# STM32U5G7 register map
File version: 1.3
CPU: CM33 r0p1, little endian, MPU, FPU, 4 interrupt priority bits
Registers are 32-bit, read-write, reset 0x0 unless marked. A register's access mark holds for its fields unless they carry their own. Offsets are from the block's base; [hi:lo] are bit positions; {n}, {i} and the like mark numbered series; 'fields as' and 'values as' point back to an identical list.

## MDF1 — Multi-function digital filter
Base 0x40025000
Same registers: SEC_MDF1 0x50025000
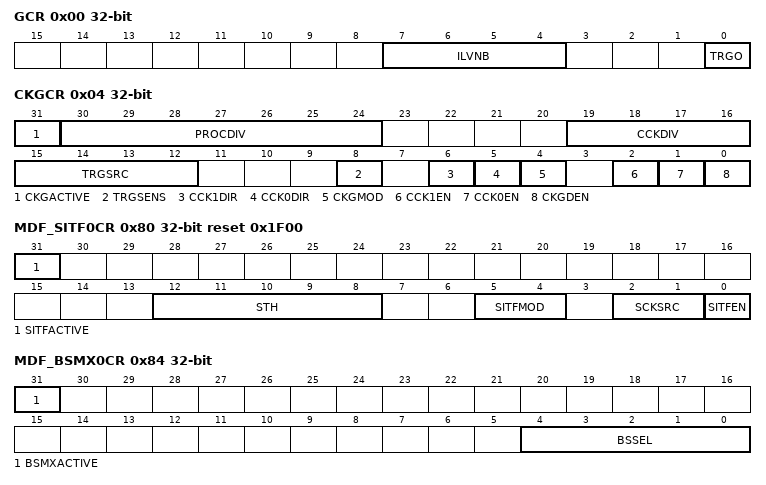
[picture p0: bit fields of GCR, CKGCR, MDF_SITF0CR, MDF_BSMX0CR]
0x00 GCR — MDF global control register
  [7:4] ILVNB, [0] TRGO
0x04 CKGCR — MDF clock generator control register
  [31] CKGACTIVE, [30:24] PROCDIV, [19:16] CCKDIV, [15:12] TRGSRC, [8] TRGSENS, [6] CCK1DIR, [5] CCK0DIR, [4] CKGMOD, [2] CCK1EN, [1] CCK0EN, [0] CKGDEN
0x80 MDF_SITF0CR access per field reset 0x1F00 — This register is used to control the serial interfaces (SITFx).
  [31] SITFACTIVE ro — Serial interface Active flag Set and cleared by hardware. This flag must be used by the application in order to check if the serial interface is effectively enabled (active) or not. The protected fields of this function can only be updated when the SITFACTIVE is set , please refer to Section 1.4.15: Register protection for details. The delay between a transition on SITFEN and a transition on SITFACTIVE is 2 periods of AHB clock and 2 periods of mdf_proc_ck. - 0: The serial interface is not active, and can be configured if needed - 1: The serial interface is active, and protected fields cannot be configured.
  [12:8] STH rw — Manchester Symbol threshold / SPI threshold Set and cleared by software. This field is used for Manchester mode, in order to define the expected symbol threshold levels. Please refer to Section : Manchester mode for details on computation. In addition this field is used to define the timeout value for the clock absence detection in Normal SPI mode. Values of STH[4:0] lower than 4 are invalid. This field can be write-protected, please refer to Section 1.4.15: Register protection for details.
  [5:4] SITFMOD rw — Serial interface type Set and cleared by software. This field is used to defined the serial interface type. - 00: LF_MASTER (Low-Frequency MASTER) SPI mode - 01: Normal SPI mode - 10: Manchester mode: rising edge = logic 0, falling edge = logic 1 - 11: Manchester mode: rising edge = logic 1, falling edge = logic 0 This field can be write-protected, please refer to Section 1.4.15: Register protection for details.
  [2:1] SCKSRC rw — Serial clock source Set and cleared by software. This bit is used to select the clock source of the serial interface. - 00: Serial clock source is MDF_CCK0 - 01: Serial clock source is MDF_CCK1 1x: Serial clock source is MDF_CKIx, not allowed in LF_MASTER SPI mode This field can be write-protected, please refer to Section 1.4.15: Register protection for details.
  [0] SITFEN rw — Serial interface enable Set and cleared by software. This bit is used to enable/disable the serial interface. - 0: Serial interface disabled - 1: Serial interface enabled
0x84 MDF_BSMX0CR access per field — This register is used to select the bitstream to be provided to the corresponding digital filter and to the SCD.
  [31] BSMXACTIVE ro — BSMX Active flag Set and cleared by hardware. This flag must be used by the application in order to check if the BSMX is effectively enabled (active) or not. BSSEL[4:0] can only be updated when the BSMXACTIVE is set . The BSMXACTIVE flag is a logical between OLDACTIVE, DFLTACTIVE, and SCDACTIVE flags. Both of them must be set in order update BSSEL[4:0] field. - 0: The BSMX is not active, and can be configured if needed - 1: The BSMX is active, and protected fields cannot be configured.
  [4:0] BSSEL rw — Bitstream Selection Set and cleared by software. This field is used to select the bitstream to be processed for the digital filter x and for the SCDx. The size of this field depends on the number of DFLTx instantiated. If the BSSEL is selecting an input which is not instantiated, the MDF will select the valid stream bs[x]_F having the higher index number. - 00000: The bitstream bs[0]_R is provided to DFLTx and SCDx - 00001: The bitstream bs[0]_F is provided to DFLTx and SCDx - 00010: The bitstream bs[1]_R is provided to DFLTx and SCDx (if instantiated) - 00011: The bitstream bs[1]_F is provided to DFLTx and SCDx (if instantiated) ... - 11110: The bitstream bs[15]_R is provided to DFLTx and SCDx (if instantiated) - 11111: The bitstream bs[15]_F is provided to DFLTx and SCDx (if instantiated) This field can be write-protected, please refer to Section 1.4.15: Register protection for details.
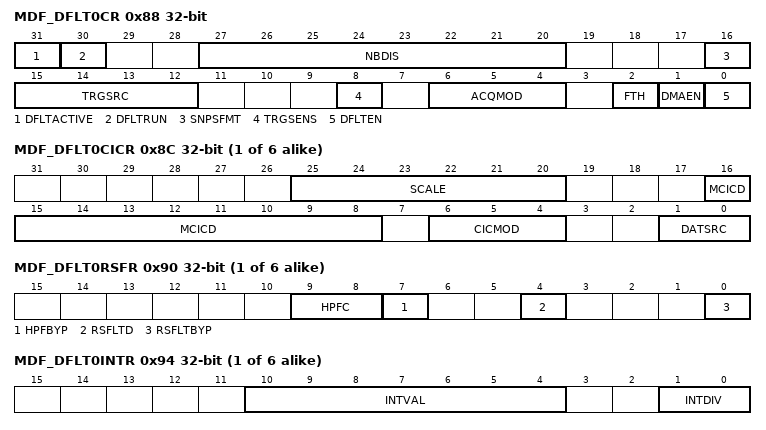
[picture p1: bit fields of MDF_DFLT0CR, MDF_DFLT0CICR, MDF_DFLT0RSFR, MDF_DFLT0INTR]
0x88 MDF_DFLT0CR access per field — This register is used to control the digital filter x.
  [31] DFLTACTIVE ro — Digital filter Active Flag Set and cleared by hardware. This bit indicates if the digital filter is active: can be running or waiting for events. - 0: The digital filter is not active, and can be re-enabled again (via DFLTEN bit) if needed - 1: The digital filter is active
  [30] DFLTRUN ro — Digital filter Run Status Flag Set and cleared by hardware. This bit indicates if the digital filter is running or not. - 0: The digital filter is not running, and ready to accept a new trigger event - 1: The digital filter is running
  [27:20] NBDIS rw — Number of samples to be discarded Set and cleared by software. This field is used to define the number of samples to be discarded every time the DFLTx is re-started. - 0: no sample discarded - 1: 1 sample discarded - 2: 2 samples discarded ... - 255: 255 samples discarded This field can be write-protected, please refer to Section 1.4.15: Register protection for details.
  [16] SNPSFMT rw — Snapshot data format Set and cleared by software. This field is used to select the data format for the snapshot mode. - 0: The integrator counter (INT_CNT) is not inserted into the MDF_SNPSxDR register, leaving a data resolution of 23 bits. - 1: The integrator counter (INT_CNT) is inserted at position [15:9] of MDF_SNPSxDR register, leaving a data resolution of 16 bits. This field can be write-protected, please refer to Section 1.4.15: Register protection for details.
  [15:12] TRGSRC rw — Digital filter Trigger signal selection, Set and cleared by software. This field is used to select which external signals is used as trigger for the corresponding filter. - 0000: TRGO is selected - 0001: OLDx event is selected - 0010: mdf_trg[0] is selected ... - 1111: mdf_trg[13] is selected This field can be write-protected, please refer to Section 1.4.15: Register protection for details.
  [8] TRGSENS rw — Digital filter Trigger sensitivity selection Set and cleared by software. This field is used to select the trigger sensitivity of the external signals - 0: A rising edge event triggers the acquisition - 1: A falling edge even triggers the acquisition Note that when the trigger source is TRGO or OLDx event, TRGSENS value is not taken into account. When TRGO is selected, the sensitivity is forced to falling edge, when OLDx event is selected, the sensitivity is forced to rising edge. This field can be write-protected, please refer to Section 1.4.15: Register protection for details.
  [6:4] ACQMOD rw — Digital filter Trigger mode Set and cleared by software. This field is used to select the filter trigger mode. - 000: Asynchronous, continuous acquisition mode - 001: Asynchronous, single-shot acquisition mode - 010: Synchronous, continuous acquisition mode - 011: Synchronous, single-shot acquisition mode - 100: Window, continuous acquisition mode - 101: Synchronous, snapshot mode others: same a 000 This field can be write-protected, please refer to Section 1.4.15: Register protection for details.
  [2] FTH rw — RXFIFO Threshold selection Set and cleared by software.
  [1] DMAEN rw — DMA Requests Enable Set and cleared by software. This bit is used to control the generation of DMA request in order to transfer the processed samples into the memory. - 0: The DMA interface for the corresponding digital filter is disabled - 1: The DMA interface for the corresponding digital filter is enabled This field can be write-protected, please refer to Section 1.4.15: Register protection for details.
  [0] DFLTEN wo — Digital Filter Enable Set and cleared by software. This bit is used to control the start of acquisition of the corresponding digital filter path. The behavior of this bit depends on ACQMOD and external events. or the acquisition starts when the proper trigger event occurs if ACQMOD = 01x . The serial or parallel interface delivering the samples shall be enabled as well. - 0: The acquisition is stopped immediately - 1: The acquisition is immediately started if ACQMOD = 00x or 1xx ,
{0x8C+0x80*i} MDF_DFLT{i}CICR (i=0..5) — This register is used to control the main CIC filter.
  [25:20] SCALE — Scaling factor selection Set and cleared by software. This field is used to allow the application to select the gain to be applied at CIC output. Please refer to Table 13: Possible gain values for details. If the application attempts to write a new gain value while the previous one is not yet applied, this new gain value is ignored. Reading back the SCALE[5:0] field will inform the application on the current gain value. - 100000: - 48.2 dB, or shift right by 8 bits (default value) - 100001: - 44.6 dB, - 100010: - 42.1 dB, or shift right by 7 bits - 100011: - 38.6 dB, ... - 101110: -6 dB, or shift right by 1 bit - 101111: -2.5 dB, - 000000: 0 dB - 000001: + 3.5 dB, - 000010: + 6 dB, or shift left by 1 bit ... - 011000: + 72 dB, or shift left by 12 bits
  [16:8] MCICD — CIC decimation ratio selection Set and cleared by software. This bit is used to allow the application to select the decimation ratio of the CIC. Decimation ratio smaller than 2 is not allowed. The decimation ratio is given by (CICDEC+1). - 0: Decimation ratio is 2 - 1: Decimation ratio is 2 - 2: Decimation ratio is 3 - 3: Decimation ratio is 4 ... - 511: Decimation ratio is 512 This field can be write-protected, please refer to Section 1.4.15: Register protection for details.
  [6:4] CICMOD — Select the CIC mode Set and cleared by software. This field allows the application to select the configuration and the order of the MCIC. When CICMOD[2:0] is equal to 0xx , the CIC is split into two filters: - The main CIC (MCIC) - The auxiliary CIC (ACIC), used for the out-off limit detector - 000: The CIC is split into 2 filters, and the main CIC (MCIC) is configured in FastSinc filter - 001: The CIC is split into 2 filters, and the main CIC (MCIC) is configured in Sinc1 filter - 010: The CIC is split into 2 filters, and the main CIC (MCIC) is configured in Sinc2 filter - 011: The CIC is split into 2 filters, and the main CIC (MCIC) is configured in Sinc3 filter - 100: The CIC is configured in single sinc4 filter others: The CIC is configured in single sinc5 filter This field can be write-protected, please refer to Section 1.4.15: Register protection for details.
  [1:0] DATSRC — Source data for the digital filter Set and cleared by software. 0x: Select the stream coming from the BSMX - 10: Select the stream coming from the ADCITF1 - 11: Select the stream coming from the ADCITF2 This field can be write-protected, please refer to Section 1.4.15: Register protection for details.
{0x90+0x80*i} MDF_DFLT{i}RSFR (i=0..5) — This register is used to control the reshape and HPF filters.
  [9:8] HPFC — High-pass filter cut-off frequency Set and cleared by software. This field is used to select the cut-off frequency of the high-pass filter. FPCM represents the sampling frequency at HPF input. - 00: Cut-off frequency = 0.000625 x FPCM - 01: Cut-off frequency = 0.00125 x FPCM - 10: Cut-off frequency = 0.00250 x FPCM - 11: Cut-off frequency = 0.00950 x FPCM This field can be write-protected, please refer to Section 1.4.15: Register protection for details.
  [7] HPFBYP — High-Pass Filter bypass Set and cleared by software. This bit is used to bypass the high-pass filter. - 0: The high pass filter is not bypassed (Default value) - 1: The high pass filter is bypassed This field can be write-protected, please refer to Section 1.4.15: Register protection for details.
  [4] RSFLTD — Reshaper filter decimation ratio Set and cleared by software. This bit is used to select the decimation ratio for the reshape filter - 0: Decimation ratio is 4 (Default value) - 1: Decimation ratio is 1 This field can be write-protected, please refer to Section 1.4.15: Register protection for details.
  [0] RSFLTBYP — Reshaper filter bypass Set and cleared by software. This bit is used to bypass the reshape filter and its decimation block. - 0: The reshape filter is not bypassed (Default value) - 1: The reshape filter is bypassed This field can be write-protected, please refer to Section 1.4.15: Register protection for details.
{0x94+0x80*i} MDF_DFLT{i}INTR (i=0..5) — This register is used to the integrator (INT) settings.
  [10:4] INTVAL — Integration value selection Set and cleared by software. This field is used to select the integration value. - 0: The integration value is 1, meaning bypass mode (default after reset) - 1: The integration value is 2 - 2: The integration value is 3 ... - 127: The integration value is 128 This field can be write-protected, please refer to Section 1.4.15: Register protection for details.
  [1:0] INTDIV — Integrator output division Set and cleared by software. This bit is used to rescale the signal at the integrator output in order keep the data width lower than 24 bits. - 00: The integrator data outputs are divided by 128 (Default value) - 01: The integrator data outputs are divided by 32 - 10: The integrator data outputs are divided by 4 - 11: The integrator data outputs are not divided This field can be write-protected, please refer to Section 1.4.15: Register protection for details.
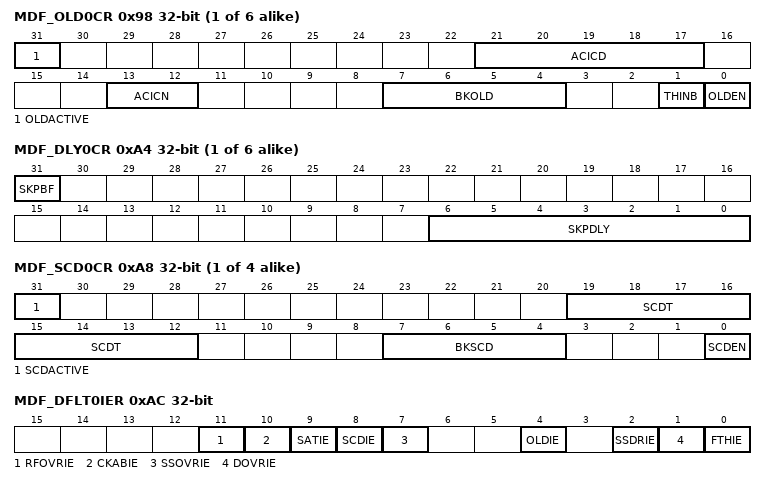
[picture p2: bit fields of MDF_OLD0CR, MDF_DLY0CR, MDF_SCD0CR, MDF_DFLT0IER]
{0x98+0x80*i} MDF_OLD{i}CR access per field (i=0..5) — This register is used to configure the Out-of Limit Detector function.
  [31] OLDACTIVE ro — OLD Active flag Set and cleared by hardware. This flag must be used by the application in order to check if the OLD is effectively enabled (active) or not. The protected fields and registers of this function can only be updated when the OLDACTIVE is set to , please refer to Section 1.4.15: Register protection for details. The delay between a transition on OLDEN and a transition on OLDACTIVE is 2 periods of AHB clock and 2 periods of mdf_proc_ck. - 0: The OLD is not active, and can be configured if needed - 1: The OLD is active, and protected fields cannot be configured.
  [21:17] ACICD rw — OLD CIC decimation ratio selection Set and cleared by software. This field is used to allow the application to select the decimation ratio of the ACIC. This field is only taken into account by the MDF when CICMOD[2:0] = 0xx . The decimation ratio is given by (ACICD+1). - 0: Decimation ratio is 1 - 1: Decimation ratio is 2 - 2: Decimation ratio is 3 - 3: Decimation ratio is 4 ... - 31: Decimation ratio is 32 This field can be write-protected, please refer to Section 1.4.15: Register protection for details.
  [13:12] ACICN rw — OLD CIC order selection Set and cleared by software. This field allows the application to select the type, and the order of the ACIC. This field is only taken into account by the MDF when CICMOD[2:0] = 0xx . - 00: FastSinc filter type - 01: Sinc1 filter type - 10: Sinc2 filter type - 11: Sinc3 filter type This field can be write-protected, please refer to Section 1.4.15: Register protection for details.
  [7:4] BKOLD rw — Break signal assignment for out-of limit detector Set and cleared by software. BKOLD[i] = 0: Break signal (mdf_break[i]) is not assigned to threshold event BKOLD[i] = 1: Break signal (mdf_break[i]) is assigned to threshold event This field can be write-protected, please refer to Section 1.4.15: Register protection for details.
  [1] THINB rw — Threshold In band Set and cleared by software. - 0: The OLD generates an event if the signal is lower than OLDTHL OR higher than OLDTHH (Default value) - 1: The OLD generates an event if the signal is lower than OLDTHH AND higher than OLDTHL This field can be write-protected, please refer to Section 1.4.15: Register protection for details.
  [0] OLDEN rw — Over-Current Detector Enable Set and cleared by software. - 0: The OLD is disabled (Default value) - 1: The OLD is enabled, including the ACIC filter working in continuous mode.
{0x9C+0x80*i} MDF_OLD{i}THLR (i=0..5) — This register is used for the adjustment of the Out-off Limit low threshold.
  [25:0] OLDTHL — OLD Low Threshold Value Set and cleared by software. OLDTHL represents a 26-bit signed value. The real threshold compared to the signal provided by the filter is OLDTHL. This field can be write-protected, please refer to Section 1.4.15: Register protection for details.
{0xA0+0x80*i} MDF_OLD{i}THHR (i=0..5) — This register is used for the adjustment of the Out-off Limit high threshold.
  [25:0] OLDTHH — OLD High Threshold Value Set and cleared by software. OLDTHH represents a 26-bit signed value. The real threshold compared to the signal provided by the filter is OLDTHH. This field can be write-protected, please refer to Section 1.4.15: Register protection for details
{0xA4+0x80*i} MDF_DLY{i}CR access per field (i=0..5) — This register is used for the adjustment stream delays.
  [31] SKPBF ro — Skip Busy flag Set and cleared by hardware. Shall be used in order to control if the delay sequence is completed. - 0: Reading 0 means that the MDF is ready to accept a new value into SKPDLY[6:0]. - 1: Reading 1 means that last valid SKPDLY[6:0] is still under precessing.
  [6:0] SKPDLY rw — Delay to apply to a bitstream Set and cleared by software. Defines the number of input samples that will be skipped. Skipping is applied immediately after writing to this field, if SKPBF = 0 , and the corresponding bit DFLTEN = 1 . If SKPBF = 1 the value written into the register is ignored by the delay state machine. - 0: No input sample skipped, - 1: 1 input sample skipped, ... - 127: 127 input sample skipped,
{0xA8+0x80*i} MDF_SCD{i}CR access per field (i=0..3) — This register is used for the adjustment stream delays.
  [31] SCDACTIVE ro — SCD Active flag Set and cleared by hardware. This flag must be used by the application in order to check if the SCD is effectively enabled (active) or not. The protected fields of this function can only be updated when the SCDACTIVE is set to a , please refer to Section 1.4.15: Register protection for details. The delay between a transition on SCDEN and a transition on SCDACTIVE is 2 periods of AHB clock and 2 periods of mdf_proc_ck. - 0: The SCD is not active, and can be configured if needed - 1: The SCD is active, and protected fields cannot be configured.
  [19:12] SCDT rw — Short-circuit detector threshold Set and cleared by software. These bits are written by software to define the threshold counter for the short-circuit detector. If this value is reached, then a short-circuit detector event occurs on a given input stream. - 0: 2 consecutive 1 s or 0 s will generate an event, - 1: 2 consecutive 1 s or 0 s will generate an event - 2: 3 consecutive 1 s or 0 s will generate an event, ... - 255: 256 consecutive 1 s or 0 s will generate an event, This field can be write-protected, please refer to Section 1.4.15: Register protection for details.
  [7:4] BKSCD rw — Break signal assignment for short circuit detector Set and cleared by software. BKSCD[i] = 0: Break signal (mdf_break[i]) is not assigned to this SCD event BKSCD[i] = 1: Break signal (mdf_break[i]) is assigned to this SCD event This field can be write-protected, please refer to Section 1.4.15: Register protection for details.
  [0] SCDEN rw — Short circuit detector enable Set and cleared by software. - 0: The short circuit detector is disabled, - 1: The short circuit detector is enabled,
0xAC MDF_DFLT0IER — This register is used for allowing or not the events to generate an interrupt.
  [11] RFOVRIE — Reshape Filter Overrun interrupt enable Set and cleared by software. - 0: Reshape filter overrun interrupt disabled - 1: Reshape filter overrun interrupt enabled
  [10] CKABIE — Clock absence detection interrupt enable Set and cleared by software. - 0: Clock absence interrupt disabled - 1: Clock absence interrupt enabled
  [9] SATIE — Saturation detection interrupt enable Set and cleared by software. - 0: Saturation interrupt disabled - 1: Saturation interrupt enabled
  [8] SCDIE — Short-Circuit Detector interrupt enable Set and cleared by software. - 0: SCD interrupt disabled - 1: SCD interrupt enabled
  [7] SSOVRIE — Snapshot overrun interrupt enable Set and cleared by software. - 0: Snapshot overrun interrupt disabled - 1: Snapshot overrun interrupt enabled
  [4] OLDIE — Out-of Limit interrupt enable Set and cleared by software. - 0: OLD event interrupt disabled - 1: OLD event interrupt enabled
  [2] SSDRIE — Snapshot data ready interrupt enable Set and cleared by software. - 0: Snapshot data ready interrupt disabled - 1: Snapshot data ready interrupt enabled
  [1] DOVRIE — Data overflow interrupt enable Set and cleared by software. - 0: Data overflow interrupt disabled - 1: Data overflow interrupt enabled
  [0] FTHIE — RXFIFO threshold interrupt enable Set and cleared by software. - 0: RXFIFO threshold interrupt disabled - 1: RXFIFO threshold interrupt enabled
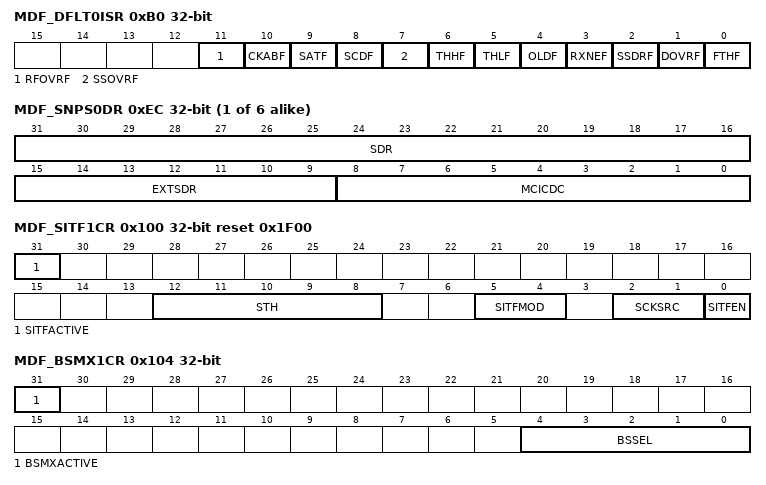
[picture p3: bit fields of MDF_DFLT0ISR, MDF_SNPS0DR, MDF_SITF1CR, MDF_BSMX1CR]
0xB0 MDF_DFLT0ISR access per field — MDF DFLT0 interrupt status register 0
  [11] RFOVRF rw — Reshape Filter Overrun detection flag Set by hardware, and cleared by software by writing this bit to 1 . - 0: Reading 0 means that no reshape filter overrun is detected, writing 0 has no effect. - 1: Reading 1 means that reshape filter overrun is detected, writing 1 clears this flag.
  [10] CKABF rw — Clock absence detection flag Set by hardware, and cleared by software by writing this bit to 1 . - 0: Reading 0 means that no clock absence is detected, writing 0 has no effect. - 1: Reading 1 means that a clock absence is detected, writing 1 clears this flag.
  [9] SATF rw — Saturation detection flag Set by hardware, and cleared by software by writing this bit to 1 . - 0: Reading 0 means that no saturation is detected, writing 0 has no effect. - 1: Reading 1 means that a saturation is detected, writing 1 clears this flag.
  [8] SCDF rw — Short-Circuit Detector flag Set by hardware, and cleared by software by writing this bit to 1 . - 0: Reading 0 means that no SCD event is detected, writing 0 has no effect. - 1: Reading 1 means that a SCD event is detected, writing 1 clears this flag.
  [7] SSOVRF rw — Snapshot overrun flag Set by hardware, and cleared by software by writing this bit to 1 . - 0: Reading 0 means that no snapshot overrun event is detected, writing 0 has no effect. - 1: Reading 1 means that a snapshot overrun event is detected, writing 1 clears this flag.
  [6] THHF ro — High threshold status flag Set by hardware, and cleared by software by writing this bit to 1 . This flag indicates the status of the high threshold comparator when the last OLD event occurred. This bit gives additional information on the conditions triggering the last OLD event. It can be cleared by writing OLDF flag to a 1. - 0: The signal was lower than OLDTHH when the last OLD event occurred. - 1: The signal was higher than OLDTHH when the last OLD event occurred.
  [5] THLF ro — Low threshold status flag Set by hardware, and cleared by software by writing this bit to 1 . This flag indicates the status of the low threshold comparator when the last OLD event occurred. This bit gives additional information on the conditions triggering the last OLD event. It can be cleared by writing OLDF flag to a 1. - 0: The signal was higher than OLDTHL when the last OLD event occurred. - 1: The signal was lower than OLDTHL when the last OLD event occurred.
  [4] OLDF rw — Out-of Limit Detector flag Set by hardware, and cleared by software by writing this bit to 1 . - 0: Reading 0 means that no OLD event is detected, writing 0 has no effect. - 1: Reading 1 means that an OLD event is detected, writing 1 clears THHF, THLF and OLDF flags.
  [3] RXNEF ro — RXFIFO Not Empty flag Set and cleared by hardware according to the RXFIFO level. - 0: Reading 0 means that the RXFIFO is empty. - 1: Reading 1 means that the RXFIFO is not empty.
  [2] SSDRF rw — Snapshot data ready flag Set by hardware, and cleared by software by writing this bit to 1 . - 0: Reading 0 means that no data is available on , writing 0 has no effect. - 1: Reading 1 means that a new data is available on , writing 1 clears this flag.
  [1] DOVRF rw — Data overflow flag Set by hardware, and cleared by software by writing this bit to 1 . - 0: Reading 0 means that no overflow is detected, writing 0 has no effect. - 1: Reading 1 means that an overflow is detected, writing 1 clears this flag.
  [0] FTHF ro
{0xB4+0x80*i} MDF_OEC{i}CR (i=0..5) — This register contains the offset compensation value.
  [25:0] OFFSET — Offset error compensation Set and cleared by software. If the application attempts to write a new offset value while the previous one is not yet applied, this new offset value is ignored. Reading back the OFFSET[25:0] field will inform the application on the current offset value. OFFSET[25:0] represents the value to be subtracted to the signal before going to the SCALE.
{0xEC+0x80*i} MDF_SNPS{i}DR ro (i=0..5) — This register is used to read the data processed by each digital filter in snapshot mode.
  [31:16] SDR — Contains the 16 MSB of the last valid data processed by the digital filter.
  [15:9] EXTSDR — Extended data size If SNPSFMT = 0 , EXTSDR[6:0] contains the bit 7 to 1 of the last valid data processed by the digital filter, If SNPSFMT = 1 , this field contains the INT accumulator counter value at the moment of the last trigger event occurs (INT_CNT).
  [8:0] MCICDC — Contains the MCIC decimation counter value at the moment of the last trigger event occurs (MCIC_CNT)
{0xF0+0x80*i} MDF_DFLT{i}DR ro (i=0..5) — This register is used to read the data processed by each digital filter.
  [31:8] DR — Data processed by digital filter.
0x100 MDF_SITF1CR access per field reset 0x1F00 — This register is used to control the serial interfaces (SITFx).
  [31] SITFACTIVE ro — Serial interface Active flag
  [12:8] STH rw — Manchester Symbol threshold / SPI threshold Set and cleared by software. This field is used for Manchester mode, in order to define the expected symbol threshold levels. Please refer to Section : Manchester mode for details on computation. In addition this field is used to define the timeout value for the clock absence detection in Normal SPI mode. Values of STH[4:0] lower than 4 are invalid. This field can be write-protected, please refer to Section 1.4.15: Register protection for details.
  [5:4] SITFMOD rw — Serial interface type Set and cleared by software. This field is used to defined the serial interface type. - 00: LF_MASTER (Low-Frequency MASTER) SPI mode - 01: Normal SPI mode - 10: Manchester mode: rising edge = logic 0, falling edge = logic 1 - 11: Manchester mode: rising edge = logic 1, falling edge = logic 0 This field can be write-protected, please refer to Section 1.4.15: Register protection for details.
  [2:1] SCKSRC rw — Serial clock source Set and cleared by software. This bit is used to select the clock source of the serial interface. - 00: Serial clock source is MDF_CCK0 - 01: Serial clock source is MDF_CCK1 1x: Serial clock source is MDF_CKIx, not allowed in LF_MASTER SPI mode This field can be write-protected, please refer to Section 1.4.15: Register protection for details.
  [0] SITFEN rw — Serial interface enable Set and cleared by software. This bit is used to enable/disable the serial interface. - 0: Serial interface disabled - 1: Serial interface enabled
0x104 MDF_BSMX1CR access per field — This register is used to select the bitstream to be provided to the corresponding digital filter and to the SCD.
  fields as MDF_BSMX0CR
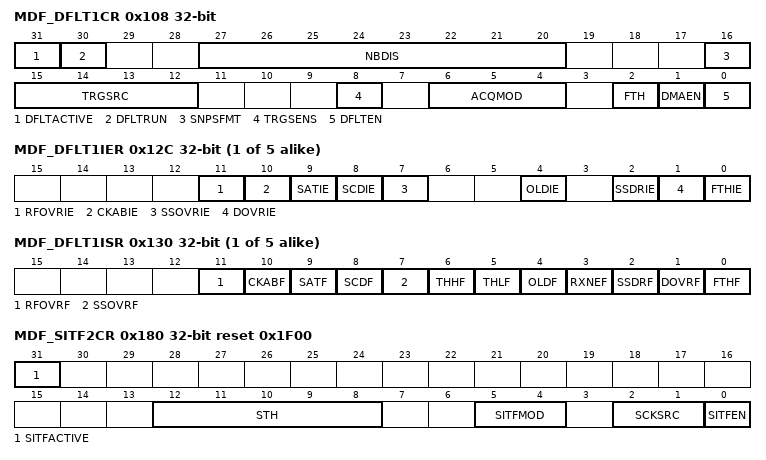
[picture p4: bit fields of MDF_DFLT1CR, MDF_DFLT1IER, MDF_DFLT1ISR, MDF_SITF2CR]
0x108 MDF_DFLT1CR access per field — This register is used to control the digital filter x.
  [31] DFLTACTIVE ro — Digital filter Active Flag Set and cleared by hardware. This bit indicates if the digital filter is active: can be running or waiting for events. - 0: The digital filter is not active, and can be re-enabled again (via DFLTEN bit) if needed - 1: The digital filter is active
  [30] DFLTRUN ro — Digital filter Run Status Flag Set and cleared by hardware. This bit indicates if the digital filter is running or not. - 0: The digital filter is not running, and ready to accept a new trigger event - 1: The digital filter is running
  [27:20] NBDIS rw — Number of samples to be discarded Set and cleared by software. This field is used to define the number of samples to be discarded every time the DFLTx is re-started. - 0: no sample discarded - 1: 1 sample discarded - 2: 2 samples discarded ... - 255: 255 samples discarded This field can be write-protected, please refer to Section 1.4.15: Register protection for details.
  [16] SNPSFMT rw — Snapshot data format Set and cleared by software. This field is used to select the data format for the snapshot mode. - 0: The integrator counter (INT_CNT) is not inserted into the MDF_SNPSxDR register, leaving a data resolution of 23 bits. - 1: The integrator counter (INT_CNT) is inserted at position [15:9] of MDF_SNPSxDR register, leaving a data resolution of 16 bits. This field can be write-protected, please refer to Section 1.4.15: Register protection for details.
  [15:12] TRGSRC rw — Digital filter Trigger signal selection, Set and cleared by software. This field is used to select which external signals is used as trigger for the corresponding filter. - 0000: TRGO is selected - 0001: OLDx event is selected - 0010: mdf_trg[0] is selected ... - 1111: mdf_trg[13] is selected This field can be write-protected, please refer to Section 1.4.15: Register protection for details.
  [8] TRGSENS rw — Digital filter Trigger sensitivity selection Set and cleared by software. This field is used to select the trigger sensitivity of the external signals - 0: A rising edge event triggers the acquisition - 1: A falling edge even triggers the acquisition Note that when the trigger source is TRGO or OLDx event, TRGSENS value is not taken into account. When TRGO is selected, the sensitivity is forced to falling edge, when OLDx event is selected, the sensitivity is forced to rising edge. This field can be write-protected, please refer to Section 1.4.15: Register protection for details.
  [6:4] ACQMOD rw — Digital filter Trigger mode Set and cleared by software. This field is used to select the filter trigger mode. - 000: Asynchronous, continuous acquisition mode - 001: Asynchronous, single-shot acquisition mode - 010: Synchronous, continuous acquisition mode - 011: Synchronous, single-shot acquisition mode - 100: Window, continuous acquisition mode - 101: Synchronous, snapshot mode others: same a 000 This field can be write-protected, please refer to Section 1.4.15: Register protection for details.
  [2] FTH rw — RXFIFO Threshold selection Set and cleared by software. This bit is used to select the RXFIFO threshold. This bit is not significant for RXFIFOs working in interleaved transfer mode. Refer to Section 1.4.13.4: Using the interleaved transfer mode for details. - 0: RXFIFO threshold event generated when the RXFIFO is not empty - 1: RXFIFO threshold event generated when the RXFIFO is half-full This field can be write-protected, please refer to Section 1.4.15: Register protection for details.
  [1] DMAEN rw — DMA Requests Enable Set and cleared by software. This bit is used to control the generation of DMA request in order to transfer the processed samples into the memory. - 0: The DMA interface for the corresponding digital filter is disabled - 1: The DMA interface for the corresponding digital filter is enabled This field can be write-protected, please refer to Section 1.4.15: Register protection for details.
  [0] DFLTEN wo — Digital Filter Enable Set and cleared by software. This bit is used to control the start of acquisition of the corresponding digital filter path. The behavior of this bit depends on ACQMOD and external events. or the acquisition starts when the proper trigger event occurs if ACQMOD = 01x . The serial or parallel interface delivering the samples shall be enabled as well. - 0: The acquisition is stopped immediately - 1: The acquisition is immediately started if ACQMOD = 00x or 1xx ,
{0xAC+0x80*i} MDF_DFLT{i}IER (i=1..5) — MDF DFLTx interrupt enable register x
  fields as MDF_DFLT0IER
{0xB0+0x80*i} MDF_DFLT{i}ISR access per field (i=1..5) — This register contains the status flags for each digital filter path.
  [11] RFOVRF rw — Reshape Filter Overrun detection flag Set by hardware, and cleared by software by writing this bit to 1 . - 0: Reading 0 means that no reshape filter overrun is detected, writing 0 has no effect. - 1: Reading 1 means that reshape filter overrun is detected, writing 1 clears this flag.
  [10] CKABF rw — Clock absence detection flag Set by hardware, and cleared by software by writing this bit to 1 . - 0: Reading 0 means that no clock absence is detected, writing 0 has no effect. - 1: Reading 1 means that a clock absence is detected, writing 1 clears this flag.
  [9] SATF rw — Saturation detection flag Set by hardware, and cleared by software by writing this bit to 1 . - 0: Reading 0 means that no saturation is detected, writing 0 has no effect. - 1: Reading 1 means that a saturation is detected, writing 1 clears this flag.
  [8] SCDF rw — Short-Circuit Detector flag Set by hardware, and cleared by software by writing this bit to 1 . - 0: Reading 0 means that no SCD event is detected, writing 0 has no effect. - 1: Reading 1 means that a SCD event is detected, writing 1 clears this flag.
  [7] SSOVRF rw — Snapshot overrun flag Set by hardware, and cleared by software by writing this bit to 1 . - 0: Reading 0 means that no snapshot overrun event is detected, writing 0 has no effect. - 1: Reading 1 means that a snapshot overrun event is detected, writing 1 clears this flag.
  [6] THHF ro — High threshold status flag Set by hardware, and cleared by software by writing OLDF bit to 1 . This flag indicates the status of the high threshold comparator when the last OLD event occurred. This bit gives additional information on the conditions triggering the last OLD event. It can be cleared by writing OLDF flag to a 1. - 0: The signal was lower than OLDTHH, when the last OLD event occurred - 1: The signal was higher than OLDTHH, when the last OLD event occurred
  [5] THLF ro — Low threshold status flag Set by hardware, and cleared by software by writing OLDF bit to 1 . This flag indicates the status of the low threshold comparator when the last OLD event occurred. This bit gives additional information on the conditions triggering the last OLD event. It can be cleared by writing OLDF flag to a 1. - 0: The signal was lower than OLDTHL, when the last OLD event occurred - 1: The signal was higher than OLDTHL, when the last OLD event occurred
  [4] OLDF rw — Out-of Limit Detector flag Set by hardware, and cleared by software by writing this bit to 1 . - 0: Reading 0 means that no OLD event is detected, writing 0 has no effect. - 1: Reading 1 means that an OLD event is detected, writing 1 clears THHF, THLF and OLDF flags.
  [3] RXNEF ro — RXFIFO Not Empty flag Set and cleared by hardware according to the RXFIFO level. - 0: Reading 0 means that the RXFIFO is empty. - 1: Reading 1 means that the RXFIFO is not empty.
  [2] SSDRF rw — Snapshot data ready flag Set by hardware, and cleared by software by writing this bit to 1 . - 0: Reading 0 means that no data is available on MDF_SNPSxDR, writing 0 has no effect. - 1: Reading 1 means that a new data is available on MDF_SNPSxDR, writing 1 clears this flag.
  [1] DOVRF rw — Data overflow flag Set by hardware, and cleared by software by writing this bit to 1 . - 0: Reading 0 means that no overflow is detected, writing 0 has no effect. - 1: Reading 1 means that an overflow is detected, writing 1 clears this flag.
  [0] FTHF ro — RXFIFO threshold flag Set by hardware, and cleared by software by writing this bit to 1 . - 0: Reading 0 means that the RXFIFO threshold is not reached, writing 0 has no effect. - 1: Reading 1 means that the RXFIFO reached the threshold, writing 1 clears this flag.
0x180 MDF_SITF2CR access per field reset 0x1F00 — This register is used to control the serial interfaces (SITFx).
  fields as MDF_SITF1CR
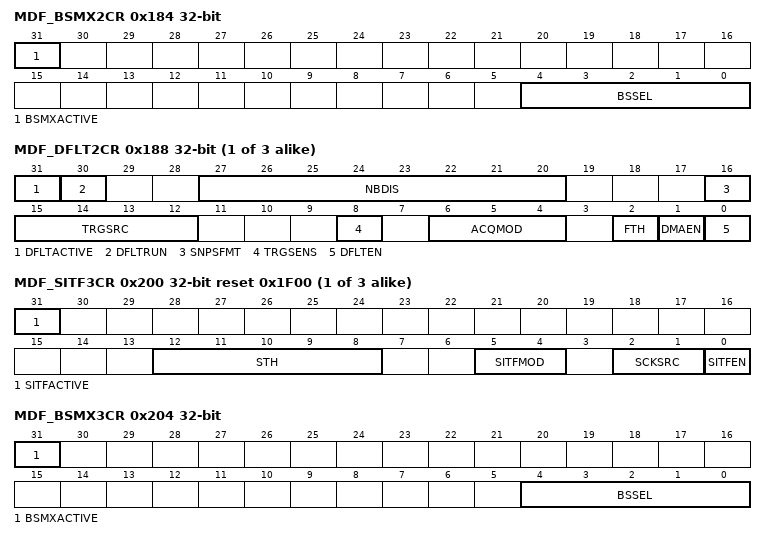
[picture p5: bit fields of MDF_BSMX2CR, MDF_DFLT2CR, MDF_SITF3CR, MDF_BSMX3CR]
0x184 MDF_BSMX2CR access per field — This register is used to select the bitstream to be provided to the corresponding digital filter and to the SCD.
  [31] BSMXACTIVE ro — BSMX Active flag Set and cleared by hardware. This flag must be used by the application in order to check if the BSMX is effectively enabled (active) or not. BSSEL[4:0] can only be updated when the BSMXACTIVE is set to a . The BSMXACTIVE flag is a logical between OLDACTIVE, DFLTACTIVE, and SCDACTIVE flags. Both of them must be set to in order update BSSEL[4:0] field. - 0: The BSMX is not active, and can be configured if needed - 1: The BSMX is active, and protected fields cannot be configured.
  [4:0] BSSEL rw — Bitstream Selection Set and cleared by software. This field is used to select the bitstream to be processed for the digital filter x and for the SCDx. The size of this field depends on the number of DFLTx instantiated. If the BSSEL is selecting an input which is not instantiated, the MDF will select the valid stream bs[x]_F having the higher index number. - 00000: The bitstream bs[0]_R is provided to DFLTx and SCDx - 00001: The bitstream bs[0]_F is provided to DFLTx and SCDx - 00010: The bitstream bs[1]_R is provided to DFLTx and SCDx (if instantiated) - 00011: The bitstream bs[1]_F is provided to DFLTx and SCDx (if instantiated) ... - 11110: The bitstream bs[15]_R is provided to DFLTx and SCDx (if instantiated) - 11111: The bitstream bs[15]_F is provided to DFLTx and SCDx (if instantiated) This field can be write-protected, please refer to Section 1.4.15: Register protection for details.
{0x88+0x80*i} MDF_DFLT{i}CR access per field (i=2..4) — This register is used to control the digital filter {i}.
  [31] DFLTACTIVE ro — Digital filter Active Flag Set and cleared by hardware. This bit indicates if the digital filter is active: can be running or waiting for events. - 0: The digital filter is not active, and can be re-enabled again (via DFLTEN bit) if needed - 1: The digital filter is active
  [30] DFLTRUN ro — Digital filter Run Status Flag Set and cleared by hardware. This bit indicates if the digital filter is running or not. - 0: The digital filter is not running, and ready to accept a new trigger event - 1: The digital filter is running
  [27:20] NBDIS rw — Number of samples to be discarded Set and cleared by software. This field is used to define the number of samples to be discarded every time the DFLTx is re-started. - 0: no sample discarded - 1: 1 sample discarded - 2: 2 samples discarded ... - 255: 255 samples discarded This field can be write-protected, please refer to Section 1.4.15: Register protection for details.
  [16] SNPSFMT rw — Snapshot data format Set and cleared by software. This field is used to select the data format for the snapshot mode. - 0: The integrator counter (INT_CNT) is not inserted into the MDF_SNPSxDR register, leaving a data resolution of 23 bits. - 1: The integrator counter (INT_CNT) is inserted at position [15:9] of MDF_SNPSxDR register, leaving a data resolution of 16 bits. This field can be write-protected, please refer to Section 1.4.15: Register protection for details.
  [15:12] TRGSRC rw — Digital filter Trigger signal selection, Set and cleared by software. This field is used to select which external signals is used as trigger for the corresponding filter. - 0000: TRGO is selected - 0001: OLDx event is selected - 0010: mdf_trg[0] is selected ... - 1111: mdf_trg[13] is selected This field can be write-protected, please refer to Section 1.4.15: Register protection for details.
  [8] TRGSENS rw — Digital filter Trigger sensitivity selection Set and cleared by software. This field is used to select the trigger sensitivity of the external signals - 0: A rising edge event triggers the acquisition - 1: A falling edge even triggers the acquisition Note that when the trigger source is TRGO or OLDx event, TRGSENS value is not taken into account. When TRGO is selected, the sensitivity is forced to falling edge, when OLDx event is selected, the sensitivity is forced to rising edge. This field can be write-protected, please refer to Section 1.4.15: Register protection for details.
  [6:4] ACQMOD rw — Digital filter Trigger mode Set and cleared by software. This field is used to select the filter trigger mode. - 000: Asynchronous, continuous acquisition mode - 001: Asynchronous, single-shot acquisition mode - 010: Synchronous, continuous acquisition mode - 011: Synchronous, single-shot acquisition mode - 100: Window, continuous acquisition mode - 101: Synchronous, snapshot mode others: same a 000 This field can be write-protected, please refer to Section 1.4.15: Register protection for details.
  [2] FTH rw — RXFIFO Threshold selection Set and cleared by software. This bit is used to select the RXFIFO threshold. This bit is not significant for RXFIFOs working in a interleaved transfer mode. Refer to Section 1.4.13.4: Using the interleaved transfer mode for details. - 0: RXFIFO threshold event generated when the RXFIFO is not empty - 1: RXFIFO threshold event generated when the RXFIFO is half-full This field can be write-protected, please refer to Section 1.4.15: Register protection for details.
  [1] DMAEN rw — DMA Requests Enable Set and cleared by software. This bit is used to control the generation of DMA request in order to transfer the processed samples into the memory. - 0: The DMA interface for the corresponding digital filter is disabled - 1: The DMA interface for the corresponding digital filter is enabled This field can be write-protected, please refer to Section 1.4.15: Register protection for details.
  [0] DFLTEN wo — Digital Filter Enable Set and cleared by software. This bit is used to control the start of acquisition of the corresponding digital filter path. The behavior of this bit depends on ACQMOD and external events. or the acquisition starts when the proper trigger event occurs if ACQMOD = 01x . The serial or parallel interface delivering the samples shall be enabled as well. - 0: The acquisition is stopped immediately - 1: The acquisition is immediately started if ACQMOD = 00x or 1xx ,
{0x80+0x80*i} MDF_SITF{i}CR access per field reset 0x1F00 (i=3..5) — This register is used to control the serial interfaces (SITFx).
  fields as MDF_SITF0CR
0x204 MDF_BSMX3CR access per field — This register is used to select the bitstream to be provided to the corresponding digital filter and to the SCD.
  [31] BSMXACTIVE ro — BSMX Active flag Set and cleared by hardware. This flag must be used by the application in order to check if the BSMX is effectively enabled (active) or not. BSSEL[4:0] can only be updated when the BSMXACTIVE is set to a . The BSMXACTIVE flag is a logical between OLDACTIVE, DFLTACTIVE, and SCDACTIVE flags. Both of them must be set to a in order update BSSEL[4:0] field. - 0: The BSMX is not active, and can be configured if needed - 1: The BSMX is active, and protected fields cannot be configured.
  [4:0] BSSEL rw — Bitstream Selection Set and cleared by software. This field is used to select the bitstream to be processed for the digital filter x and for the SCDx. The size of this field depends on the number of DFLTx instantiated. If the BSSEL is selecting an input which is not instantiated, the MDF will select the valid stream bs[x]_F having the higher index number. - 00000: The bitstream bs[0]_R is provided to DFLTx and SCDx - 00001: The bitstream bs[0]_F is provided to DFLTx and SCDx - 00010: The bitstream bs[1]_R is provided to DFLTx and SCDx (if instantiated) - 00011: The bitstream bs[1]_F is provided to DFLTx and SCDx (if instantiated) ... - 11110: The bitstream bs[15]_R is provided to DFLTx and SCDx (if instantiated) - 11111: The bitstream bs[15]_F is provided to DFLTx and SCDx (if instantiated) This field can be write-protected, please refer to Section 1.4.15: Register protection for details.
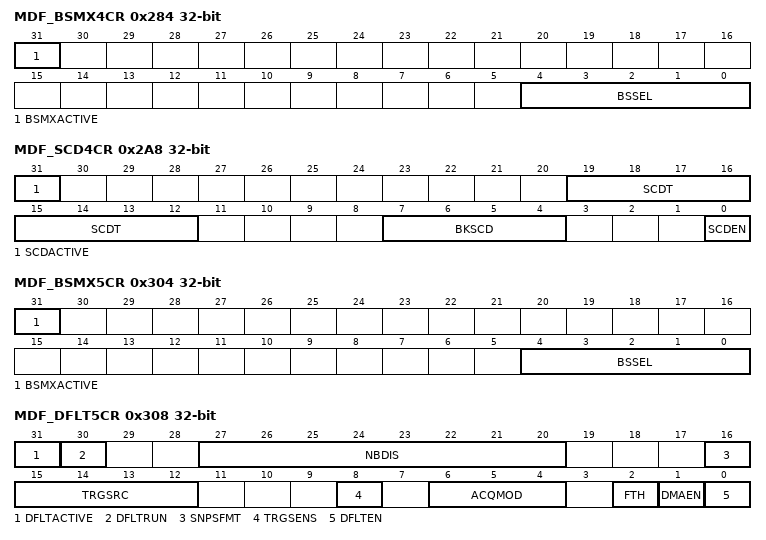
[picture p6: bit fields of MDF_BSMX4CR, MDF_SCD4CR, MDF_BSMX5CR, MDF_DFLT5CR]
0x284 MDF_BSMX4CR access per field — This register is used to select the bitstream to be provided to the corresponding digital filter and to the SCD.
  [31] BSMXACTIVE ro — BSMX Active flag Set and cleared by hardware. This flag must be used by the application in order to check if the BSMX is effectively enabled (active) or not. BSSEL[4:0] can only be updated when the BSMXACTIVE is set to . The BSMXACTIVE flag is a logical between OLDACTIVE, DFLTACTIVE, and SCDACTIVE flags. Both of them must be set to in order update BSSEL[4:0] field. - 0: The BSMX is not active, and can be configured if needed - 1: The BSMX is active, and protected fields cannot be configured.
  [4:0] BSSEL rw — Bitstream Selection Set and cleared by software. This field is used to select the bitstream to be processed for the digital filter x and for the SCDx. The size of this field depends on the number of DFLTx instantiated. If the BSSEL is selecting an input which is not instantiated, the MDF will select the valid stream bs[x]_F having the higher index number. - 00000: The bitstream bs[0]_R is provided to DFLTx and SCDx - 00001: The bitstream bs[0]_F is provided to DFLTx and SCDx - 00010: The bitstream bs[1]_R is provided to DFLTx and SCDx (if instantiated) - 00011: The bitstream bs[1]_F is provided to DFLTx and SCDx (if instantiated) ... - 11110: The bitstream bs[15]_R is provided to DFLTx and SCDx (if instantiated) - 11111: The bitstream bs[15]_F is provided to DFLTx and SCDx (if instantiated) This field can be write-protected, please refer to Section 1.4.15: Register protection for details.
0x2A8 MDF_SCD4CR access per field — This register is used for the adjustment stream delays.
  [31] SCDACTIVE ro — SCD Active flag Set and cleared by hardware. This flag must be used by the application in order to check if the SCD is effectively enabled (active) or not. The protected fields of this function can only be updated when the SCDACTIVE is set to a a , please refer to Section 1.4.15: Register protection for details. The delay between a transition on SCDEN and a transition on SCDACTIVE is 2 periods of AHB clock and 2 periods of mdf_proc_ck. - 0: The SCD is not active, and can be configured if needed - 1: The SCD is active, and protected fields cannot be configured.
  [19:12] SCDT rw — Short-circuit detector threshold Set and cleared by software. These bits are written by software to define the threshold counter for the short-circuit detector. If this value is reached, then a short-circuit detector event occurs on a given input stream. - 0: 2 consecutive 1 s or 0 s will generate an event, - 1: 2 consecutive 1 s or 0 s will generate an event - 2: 3 consecutive 1 s or 0 s will generate an event, ... - 255: 256 consecutive 1 s or 0 s will generate an event, This field can be write-protected, please refer to Section 1.4.15: Register protection for details.
  [7:4] BKSCD rw — Break signal assignment for short circuit detector Set and cleared by software. BKSCD[i] = 0: Break signal (mdf_break[i]) is not assigned to this SCD event BKSCD[i] = 1: Break signal (mdf_break[i]) is assigned to this SCD event This field can be write-protected, please refer to Section 1.4.15: Register protection for details.
  [0] SCDEN rw — Short circuit detector enable Set and cleared by software. - 0: The short circuit detector is disabled, - 1: The short circuit detector is enabled,
0x304 MDF_BSMX5CR access per field — This register is used to select the bitstream to be provided to the corresponding digital filter and to the SCD.
  fields as MDF_BSMX4CR
0x308 MDF_DFLT5CR access per field — This register is used to control the digital filter x.
  fields as MDF_DFLT1CR
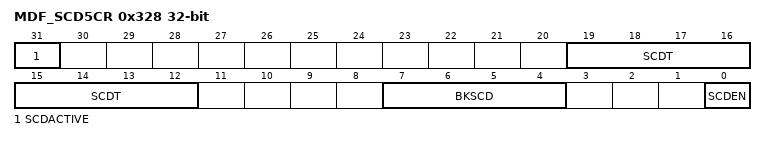
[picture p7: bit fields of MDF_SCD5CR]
0x328 MDF_SCD5CR access per field — This register is used for the adjustment stream delays.
  fields as MDF_SCD4CR
